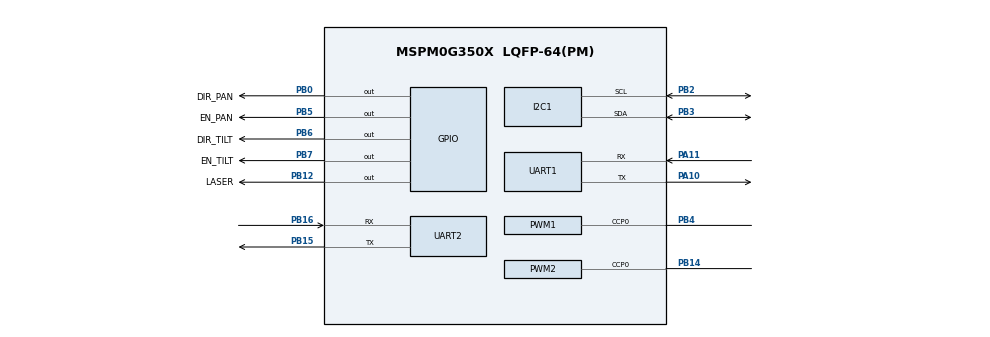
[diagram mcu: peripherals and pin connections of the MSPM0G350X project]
/**
 *
 * @cliArgs --device "MSPM0G350X" --part "Default" --package "LQFP-64(PM)" --product "mspm0_sdk@2.10.00.04"
 * @versions {"tool":"1.28.0+4696"}
 */

/**
 * Import the modules used in this configuration.
 */
const GPIO   = scripting.addModule("/ti/driverlib/GPIO", {}, false);
const GPIO1  = GPIO.addInstance();
const GPIO2  = GPIO.addInstance();
const I2C    = scripting.addModule("/ti/driverlib/I2C", {}, false);
const I2C1   = I2C.addInstance();
const PWM    = scripting.addModule("/ti/driverlib/PWM", {}, false);
const PWM1   = PWM.addInstance();
const PWM2   = PWM.addInstance();
const SYSCTL = scripting.addModule("/ti/driverlib/SYSCTL");
const UART   = scripting.addModule("/ti/driverlib/UART", {}, false);
const UART1  = UART.addInstance();
const UART2  = UART.addInstance();

/**
 * Write custom configuration values to the imported modules.
 */
GPIO1.$name                         = "GPIO_STEP";
GPIO1.port                          = "PORTB";
GPIO1.associatedPins.create(5);
GPIO1.associatedPins[0].$name       = "DIR_PAN";
GPIO1.associatedPins[0].pin.$assign = "PB0";
GPIO1.associatedPins[1].$name       = "EN_PAN";
GPIO1.associatedPins[1].pin.$assign = "PB5";
GPIO1.associatedPins[2].$name       = "DIR_TILT";
GPIO1.associatedPins[2].pin.$assign = "PB6";
GPIO1.associatedPins[3].$name       = "EN_TILT";
GPIO1.associatedPins[3].pin.$assign = "PB7";
GPIO1.associatedPins[4].$name       = "LASER";
GPIO1.associatedPins[4].pin.$assign = "PB12";

const Board = scripting.addModule("/ti/driverlib/Board", {}, false);

GPIO2.$name                               = "GPIO_LED";
GPIO2.associatedPins[0].$name             = "STATUS";
GPIO2.associatedPins[0].launchPadShortcut = "LED2GreenEn";

I2C1.$name                           = "I2C_0";
I2C1.basicEnableController           = true;
I2C1.basicControllerStandardBusSpeed = "Fast";
I2C1.intController                   = ["TXFIFO_TRIGGER","TX_DONE"];
I2C1.peripheral.$assign              = "I2C1";
I2C1.peripheral.sdaPin.$assign       = "PB3";
I2C1.peripheral.sclPin.$assign       = "PB2";
I2C1.sdaPinConfig.$name              = "ti_driverlib_gpio_GPIOPinGeneric5";
I2C1.sclPinConfig.$name              = "ti_driverlib_gpio_GPIOPinGeneric7";

PWM1.$name                              = "PWM_PAN";
PWM1.ccIndex                            = [0];
PWM1.clockDivider                       = 8;
PWM1.timerCount                         = 4000;
PWM1.interrupts                         = ["ZERO_EVENT"];
PWM1.PWM_CHANNEL_0.$name                = "ti_driverlib_pwm_PWMTimerCC0";
PWM1.PWM_CHANNEL_0.dutyCycle            = 50;
PWM1.ccp0PinConfig.direction            = scripting.forceWrite("OUTPUT");
PWM1.ccp0PinConfig.hideOutputInversion  = scripting.forceWrite(false);
PWM1.ccp0PinConfig.onlyInternalResistor = scripting.forceWrite(false);
PWM1.ccp0PinConfig.passedPeripheralType = scripting.forceWrite("Digital");
PWM1.ccp0PinConfig.$name                = "ti_driverlib_gpio_GPIOPinGeneric4";
PWM1.peripheral.$assign                 = "TIMA1";
PWM1.peripheral.ccp0Pin.$assign         = "PB4";

PWM2.$name                              = "PWM_TILT";
PWM2.ccIndex                            = [0];
PWM2.clockDivider                       = 8;
PWM2.timerCount                         = 4000;
PWM2.interrupts                         = ["ZERO_EVENT"];
PWM2.PWM_CHANNEL_0.$name                = "ti_driverlib_pwm_PWMTimerCC2";
PWM2.PWM_CHANNEL_0.dutyCycle            = 50;
PWM2.ccp0PinConfig.direction            = scripting.forceWrite("OUTPUT");
PWM2.ccp0PinConfig.hideOutputInversion  = scripting.forceWrite(false);
PWM2.ccp0PinConfig.onlyInternalResistor = scripting.forceWrite(false);
PWM2.ccp0PinConfig.passedPeripheralType = scripting.forceWrite("Digital");
PWM2.ccp0PinConfig.$name                = "ti_driverlib_gpio_GPIOPinGeneric6";
PWM2.peripheral.$assign                 = "TIMA0";
PWM2.peripheral.ccp0Pin.$assign         = "PB14";

SYSCTL.forceDefaultClkConfig = true;

UART1.$name                            = "UART0_Debug";
UART1.targetBaudRate                   = 115200;
UART1.enabledInterrupts                = ["RX"];
UART1.peripheral.$assign               = "UART0";
UART1.peripheral.rxPin.$assign         = "PA11";
UART1.peripheral.txPin.$assign         = "PA10";
UART1.txPinConfig.direction            = scripting.forceWrite("OUTPUT");
UART1.txPinConfig.hideOutputInversion  = scripting.forceWrite(false);
UART1.txPinConfig.onlyInternalResistor = scripting.forceWrite(false);
UART1.txPinConfig.passedPeripheralType = scripting.forceWrite("Digital");
UART1.txPinConfig.$name                = "ti_driverlib_gpio_GPIOPinGeneric0";
UART1.rxPinConfig.hideOutputInversion  = scripting.forceWrite(false);
UART1.rxPinConfig.onlyInternalResistor = scripting.forceWrite(false);
UART1.rxPinConfig.passedPeripheralType = scripting.forceWrite("Digital");
UART1.rxPinConfig.$name                = "ti_driverlib_gpio_GPIOPinGeneric1";

UART2.$name                            = "UART2_K230";
UART2.targetBaudRate                   = 115200;
UART2.enabledInterrupts                = ["RX"];
UART2.peripheral.$assign               = "UART2";
UART2.peripheral.rxPin.$assign         = "PB16";
UART2.peripheral.txPin.$assign         = "PB15";
UART2.txPinConfig.direction            = scripting.forceWrite("OUTPUT");
UART2.txPinConfig.hideOutputInversion  = scripting.forceWrite(false);
UART2.txPinConfig.onlyInternalResistor = scripting.forceWrite(false);
UART2.txPinConfig.passedPeripheralType = scripting.forceWrite("Digital");
UART2.txPinConfig.$name                = "ti_driverlib_gpio_GPIOPinGeneric2";
UART2.rxPinConfig.hideOutputInversion  = scripting.forceWrite(false);
UART2.rxPinConfig.onlyInternalResistor = scripting.forceWrite(false);
UART2.rxPinConfig.passedPeripheralType = scripting.forceWrite("Digital");
UART2.rxPinConfig.$name                = "ti_driverlib_gpio_GPIOPinGeneric3";

/**
 * Pinmux solution for unlocked pins/peripherals. This ensures that minor changes to the automatic solver in a future
 * version of the tool will not impact the pinmux you originally saw.  These lines can be completely deleted in order to
 * re-solve from scratch.
 */
Board.peripheral.$suggestSolution            = "DEBUGSS";
Board.peripheral.swclkPin.$suggestSolution   = "PA20";
Board.peripheral.swdioPin.$suggestSolution   = "PA19";
GPIO2.associatedPins[0].pin.$suggestSolution = "PB27";
SYSCTL.peripheral.$suggestSolution           = "SYSCTL";
